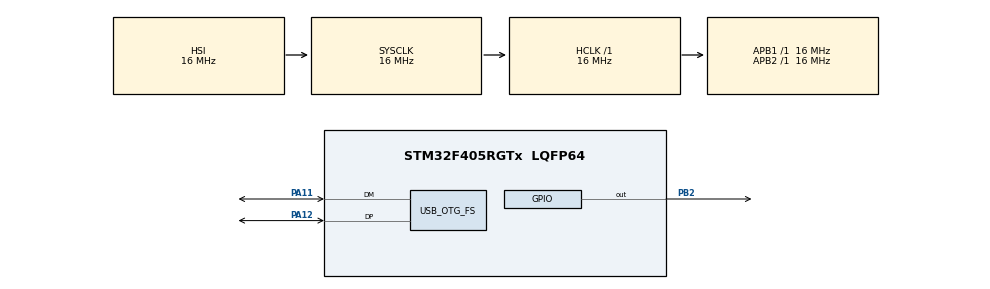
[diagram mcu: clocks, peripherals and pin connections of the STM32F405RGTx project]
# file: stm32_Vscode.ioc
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Mcu.Family=STM32F4
Mcu.Name=STM32F405RGTx
Mcu.Package=LQFP64
NVIC.OTG_FS_IRQn=true\:0\:0\:false\:false\:true\:false\:true\:true
NVIC.PriorityGroup=NVIC_PRIORITYGROUP_4
PA11.Mode=Device_Only
PA11.Signal=USB_OTG_FS_DM
PA12.Mode=Device_Only
PA12.Signal=USB_OTG_FS_DP
PA13.Mode=Serial_Wire
PA13.Signal=SYS_JTMS-SWDIO
PA14.Mode=Serial_Wire
PA14.Signal=SYS_JTCK-SWCLK
PB2.Signal=GPIO_Output
PH0-OSC_IN.Mode=HSE-External-Oscillator
PH0-OSC_IN.Signal=RCC_OSC_IN
PH1-OSC_OUT.Mode=HSE-External-Oscillator
PH1-OSC_OUT.Signal=RCC_OSC_OUT
ProjectManager.HeapSize=0x200
ProjectManager.StackSize=0x400
ProjectManager.TargetToolchain=CMake
RCC.48MHZClocksFreq_Value=48000000
RCC.AHBFreq_Value=16000000
RCC.APB1Freq_Value=16000000
RCC.APB2Freq_Value=16000000
RCC.CortexFreq_Value=16000000
RCC.HSE_VALUE=8000000
RCC.HSI_VALUE=16000000
RCC.LSE_VALUE=32768
RCC.PLLM=4
RCC.PLLN=72
RCC.PLLQ=3
RCC.SYSCLKFreq_VALUE=16000000
RCC.VCOOutputFreq_Value=144000000
USB_DEVICE.CLASS_NAME_FS=CDC
USB_DEVICE.VirtualMode-CDC_FS=Cdc
USB_DEVICE.VirtualModeFS=Cdc_FS
USB_OTG_FS.VirtualMode=Device_Only
VP_USB_DEVICE_VS_USB_DEVICE_CDC_FS.Mode=CDC_FS
board=custom

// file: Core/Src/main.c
/* USER CODE BEGIN Header */
/**
  ******************************************************************************
  * @file           : main.c
  * @brief          : Main program body
  ******************************************************************************
  * @attention
  *
  * Copyright (c) 2026 STMicroelectronics.
  * All rights reserved.
  *
  * This software is licensed under terms that can be found in the LICENSE file
  * in the root directory of this software component.
  * If no LICENSE file comes with this software, it is provided AS-IS.
  *
  ******************************************************************************
  */
/* USER CODE END Header */
#include "main.h"
#include "usb_device.h"
#include "usbd_cdc_if.h"
#include <math.h>
#include <string.h>

/* USER CODE BEGIN PD */
#define PROTO_SYNC0      0xAAU
#define PROTO_SYNC1      0x55U
#define NUM_CHANNELS     32U
#define DISPLAY_BINS     128U
#define PROTO_HDR_SIZE   7U
#define PROTO_DATA_BYTES (NUM_CHANNELS * DISPLAY_BINS * 2U)
#define PROTO_FRAME_SIZE (PROTO_HDR_SIZE + PROTO_DATA_BYTES + 2U)
#ifndef M_PI
#define M_PI 3.14159265358979323846
#endif

/* Frame cadence. Keep this comfortably above 2x the highest channel
   frequency below (see SINE_FREQ_MAX) to avoid aliasing between frames. */
#define FRAME_PERIOD_MS  50U

/* All channels share the same frequency/phase so they visibly move in
   lockstep. Change SINE_FREQ_STEP/PHASE_STEP back to non-zero if you
   intentionally want per-channel diversity again -- just raise
   FRAME_PERIOD_MS so the fastest channel is still safely sampled. */
#define SINE_FREQ_BASE   2.0f
#define SINE_FREQ_STEP   0.0f
#define SINE_PHASE_STEP  0.0f

/* USER CODE END PD */

static uint16_t g_seq = 0;

/* USER CODE BEGIN PV */

/* Double-buffered TX frames. These are ~8.2 KB each (16.4 KB total) --
   far too large for the default main stack, so they MUST be static/global,
   never a local array inside main(). */
static uint8_t frame[2][PROTO_FRAME_SIZE];

/* USER CODE END PV */

void SystemClock_Config(void);
static void MX_GPIO_Init(void);

/* USER CODE BEGIN 0 */
static uint16_t crc16_ccitt(const uint8_t *data, uint32_t len)
{
  uint16_t crc = 0xFFFFU;

  for (uint32_t i = 0; i < len; ++i)
  {
    crc ^= (uint16_t)data[i] << 8;

    for (uint8_t bit = 0; bit < 8; ++bit)
    {
      if (crc & 0x8000U)
      {
        crc = (uint16_t)((crc << 1) ^ 0x1021U);
      }
      else
      {
        crc <<= 1;
      }
    }
  }

  return crc;
}

static void build_sine_frame(uint8_t *frame_buf)
{
  uint8_t *p = frame_buf;

  /* sync */
  *p++ = PROTO_SYNC0;
  *p++ = PROTO_SYNC1;

  uint16_t seq = g_seq++;
  memcpy(p, &seq, 2);
  p += 2;

  *p++ = (uint8_t)NUM_CHANNELS;

  uint16_t nbins = DISPLAY_BINS;
  memcpy(p, &nbins, 2);
  p += 2;

  /* p is now at PROTO_HDR_SIZE (7), an odd offset -- do NOT cast this to
     uint16_t* and dereference it directly, that's an unaligned/UB access.
     Write each sample through memcpy instead. */
  uint32_t tick = HAL_GetTick();
  const float t = (float)tick / 1000.0f;

  for (uint16_t ch = 0; ch < NUM_CHANNELS; ++ch)
  {
    const float phase = (float)ch * SINE_PHASE_STEP;
    const float freq = SINE_FREQ_BASE + (float)ch * SINE_FREQ_STEP;

    for (uint16_t bin = 0; bin < DISPLAY_BINS; ++bin)
    {
      const float sine = sinf(2.0f * (float)M_PI * (freq * t + (float)bin / 32.0f + phase));
      float mag = 20000.0f + (sine + 1.0f) * 20000.0f;

      if (mag < 0.0f) mag = 0.0f;
      if (mag > 65535.0f) mag = 65535.0f;

      uint16_t sample = (uint16_t)mag;
      memcpy(p, &sample, 2);
      p += 2;
    }
  }

  uint16_t crc = crc16_ccitt(frame_buf + PROTO_HDR_SIZE, PROTO_DATA_BYTES);
  memcpy(p, &crc, 2);
}

/* USER CODE END 0 */

int main(void)
{

  /* MCU Configuration--------------------------------------------------------*/

  /* Reset of all peripherals, Initializes the Flash interface and the Systick. */
  HAL_Init();

  /* Configure the system clock */
  SystemClock_Config();

  /* Initialize all configured peripherals */
  MX_GPIO_Init();
  MX_USB_DEVICE_Init();

  /* Infinite loop */
  /* USER CODE BEGIN WHILE */
  uint8_t frame_index = 0U;
  uint32_t last_tx = 0U;
  uint32_t last_led_toggle = 0U;
  uint32_t tx_drop_count = 0U; /* bumped whenever CDC_Transmit_FS is busy */

  while (1)
  {
    uint32_t now = HAL_GetTick();

    /* Non-blocking transmit gate. No HAL_Delay() in this loop, so this
       check runs every iteration instead of being quantized to a fixed
       delay step -- the frame cadence now matches FRAME_PERIOD_MS. */
    if ((now - last_tx) >= FRAME_PERIOD_MS)
    {
      build_sine_frame(frame[frame_index]);

      if (CDC_Transmit_FS(frame[frame_index], PROTO_FRAME_SIZE) == USBD_OK)
      {
        frame_index ^= 1U;
        last_tx = now;
      }
      else
      {
        /* Host not keeping up / endpoint busy. Don't advance last_tx so
           we retry ASAP on the next loop iteration instead of waiting
           out a fixed delay; just track it so it's visible if it happens. */
        tx_drop_count++;
      }
    }

    /* Toggle the heartbeat LED every 20 ms without blocking the loop. */
    if ((now - last_led_toggle) >= 20U)
    {
      HAL_GPIO_TogglePin(GPIOB, GPIO_PIN_2);
      last_led_toggle = now;
    }

    /* USER CODE END WHILE */

  }
}

void SystemClock_Config(void)
{
  RCC_OscInitTypeDef RCC_OscInitStruct = {0};
  RCC_ClkInitTypeDef RCC_ClkInitStruct = {0};

  /** Configure the main internal regulator output voltage
  */
  __HAL_RCC_PWR_CLK_ENABLE();
  __HAL_PWR_VOLTAGESCALING_CONFIG(PWR_REGULATOR_VOLTAGE_SCALE1);

  /** Initializes the RCC Oscillators according to the specified parameters
  * in the RCC_OscInitTypeDef structure.
  */
  RCC_OscInitStruct.OscillatorType = RCC_OSCILLATORTYPE_HSI|RCC_OSCILLATORTYPE_HSE;
  RCC_OscInitStruct.HSEState = RCC_HSE_ON;
  RCC_OscInitStruct.HSIState = RCC_HSI_ON;
  RCC_OscInitStruct.HSICalibrationValue = RCC_HSICALIBRATION_DEFAULT;
  RCC_OscInitStruct.PLL.PLLState = RCC_PLL_ON;
  RCC_OscInitStruct.PLL.PLLSource = RCC_PLLSOURCE_HSE;
  RCC_OscInitStruct.PLL.PLLM = 4;
  RCC_OscInitStruct.PLL.PLLN = 72;
  RCC_OscInitStruct.PLL.PLLP = RCC_PLLP_DIV2;
  RCC_OscInitStruct.PLL.PLLQ = 3;
  if (HAL_RCC_OscConfig(&RCC_OscInitStruct) != HAL_OK)
  {
    Error_Handler();
  }

  /** Initializes the CPU, AHB and APB buses clocks
  */
  RCC_ClkInitStruct.ClockType = RCC_CLOCKTYPE_HCLK|RCC_CLOCKTYPE_SYSCLK
                              |RCC_CLOCKTYPE_PCLK1|RCC_CLOCKTYPE_PCLK2;
  RCC_ClkInitStruct.SYSCLKSource = RCC_SYSCLKSOURCE_HSI;
  RCC_ClkInitStruct.AHBCLKDivider = RCC_SYSCLK_DIV1;
  RCC_ClkInitStruct.APB1CLKDivider = RCC_HCLK_DIV1;
  RCC_ClkInitStruct.APB2CLKDivider = RCC_HCLK_DIV1;

  if (HAL_RCC_ClockConfig(&RCC_ClkInitStruct, FLASH_LATENCY_0) != HAL_OK)
  {
    Error_Handler();
  }
}

static void MX_GPIO_Init(void)
{
  GPIO_InitTypeDef GPIO_InitStruct = {0};

  /* GPIO Ports Clock Enable */
  __HAL_RCC_GPIOH_CLK_ENABLE();
  __HAL_RCC_GPIOB_CLK_ENABLE();
  __HAL_RCC_GPIOA_CLK_ENABLE();

  /*Configure GPIO pin Output Level */
  HAL_GPIO_WritePin(GPIOB, GPIO_PIN_2, GPIO_PIN_RESET);

  /*Configure GPIO pin : PB2 */
  GPIO_InitStruct.Pin = GPIO_PIN_2;
  GPIO_InitStruct.Mode = GPIO_MODE_OUTPUT_PP;
  GPIO_InitStruct.Pull = GPIO_NOPULL;
  GPIO_InitStruct.Speed = GPIO_SPEED_FREQ_LOW;
  HAL_GPIO_Init(GPIOB, &GPIO_InitStruct);

}

void Error_Handler(void)
{
  __disable_irq();
  while (1)
  {
  }
}
